# M411_unitA register map
File version: 2.0.2.2
Registers are 32-bit, read-write, reset 0x0 unless marked. A register's access mark holds for its fields unless they carry their own. Offsets are from the block's base; [hi:lo] are bit positions; {n}, {i} and the like mark numbered series.

## T16A0 — 16-bit TimerA (T16A)
Base 0x4008D000
Same registers: T16A1 0x4008E000
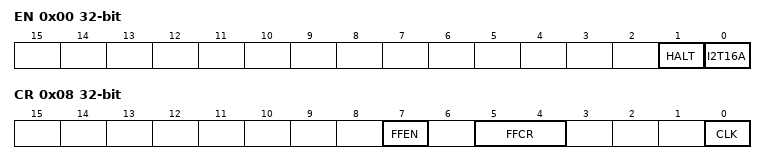
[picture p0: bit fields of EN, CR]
0x00 EN — Enable Register
  [1] HALT, [0] I2T16A
0x04 RUN
  [0] RUN
0x08 CR — Control Register
  [7] FFEN, [5:4] FFCR wo, [0] CLK
0x0C RG — Timer Register
  [15:0] RG
0x10 CP ro — Capture Register
  [15:0] CP

## I2C — I2C Bus Interface (I2C)
Base 0x400A0000
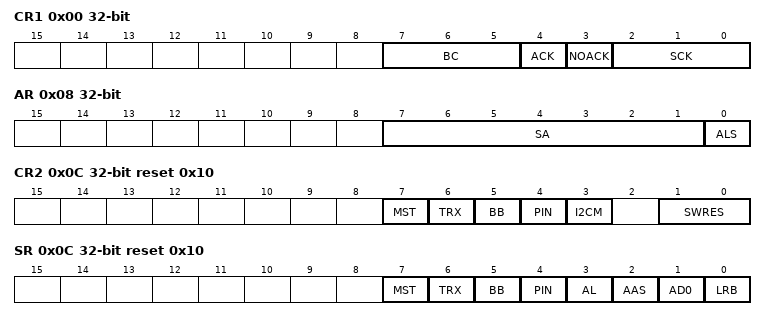
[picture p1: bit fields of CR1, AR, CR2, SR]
0x00 CR1 — I2C Control Register 1
  [7:5] BC, [4] ACK, [3] NOACK ro, [2:0] SCK
0x04 DBR — Data Buffer Register
  [7:0] DB
0x08 AR — Bus address Register
  [7:1] SA, [0] ALS
0x0C CR2 wo reset 0x10 — Control Register 1
  [7] MST, [6] TRX, [5] BB, [4] PIN, [3] I2CM, [1:0] SWRES
0x0C SR ro reset 0x10 — Status Register
  [7] MST, [6] TRX, [5] BB, [4] PIN, [3] AL, [2] AAS, [1] AD0, [0] LRB
0x10 PRS reset 0x1 — Prescaler clcok setting Register
  [4:0] PRSCK
0x14 IE — Interrupt Enable Register
  [0] IE
0x18 IR — Interrupt Register
  [0] ISIC

## INT — Interrupt Controller (INT)
Base 0x400B8000
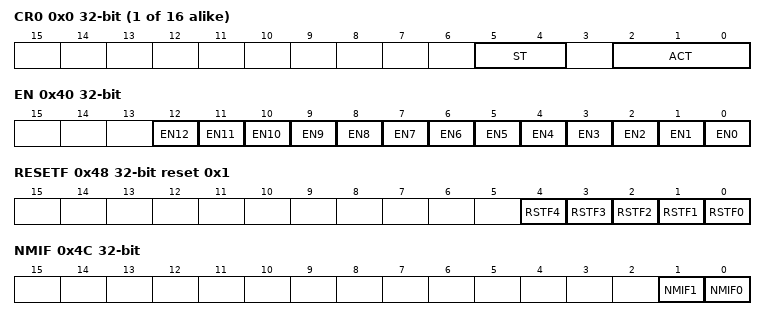
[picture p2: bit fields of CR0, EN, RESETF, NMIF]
{0x0+4i} CR{i} (i=0..15) — Control Register {i}
  [5:4] ST ro, [2:0] ACT
0x40 EN — STOP1 Mode Release Setting Register
  [n] EN{n} (n=0..12)
0x44 CLR wo — Interrupt Request Clear Register
  [3:0] CLR
0x48 RESETF reset 0x1 — Reset Flag Register
  [n] RSTF{n} (n=0..4)
0x4C NMIF ro — NMI Flag Register
  [1] NMIF1, [0] NMIF0
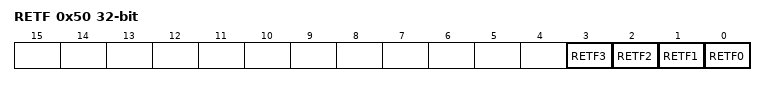
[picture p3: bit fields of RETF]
0x50 RETF — STOP2_STOP3 Release Flag Register
  [n] RETF{n} (n=0..3)
0x54 LVDST ro — SD2 Area Voltage Status Register
  [0] LVDST

## CPUIF — CPU Interface (CPUIF)
Base 0x400BC000
0x00 INTCR — Interrupt Control Regiser
  [0] INT
0x04 INTCLR — Interrupt Clear Register
  [0] CLR
0x08 INFOW — Transmit Data Register
0x0C INFOR ro reset not defined — Receive Data Register
0x10 CKCR — Clock Control Register for Unit B
  [0] CK
0x14 RSTCR — Reset Control Register for Unit B
  [0] RSTREL

## PA — Port A (PA)
Base 0x400C0000
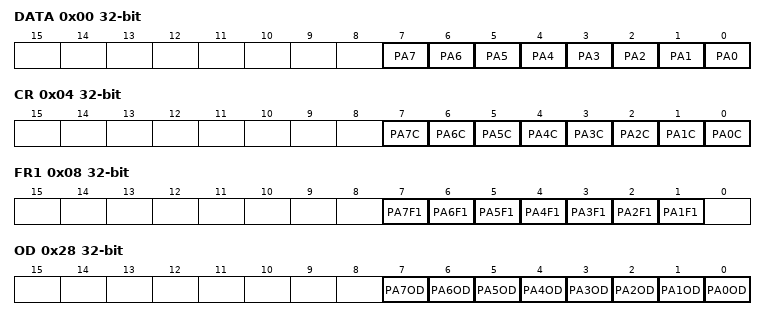
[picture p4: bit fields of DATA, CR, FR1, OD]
0x00 DATA — Port A Data Register
  [n] PA{n} (n=0..7)
0x04 CR — Port A Output Control Register
  [n] PA{n}C (n=0..7)
0x08 FR1 — Port A Function Register 1
  [n] PA{n}F1 (n=1..7)
0x28 OD — Port A Open-drain Control Register
  [n] PA{n}OD (n=0..7)
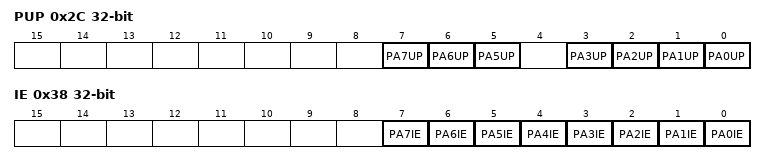
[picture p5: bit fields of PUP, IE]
0x2C PUP — Port A Pull-up Control Register
  [7] PA7UP, [6] PA6UP, [5] PA5UP, [n] PA{n}UP (n=0..3)
0x30 PDN — Port A Pull-down Control Register
  [4] PA4DN
0x38 IE — Port A Input Control Register
  [n] PA{n}IE (n=0..7)

## PB — Port B (PB)
Base 0x400C0100
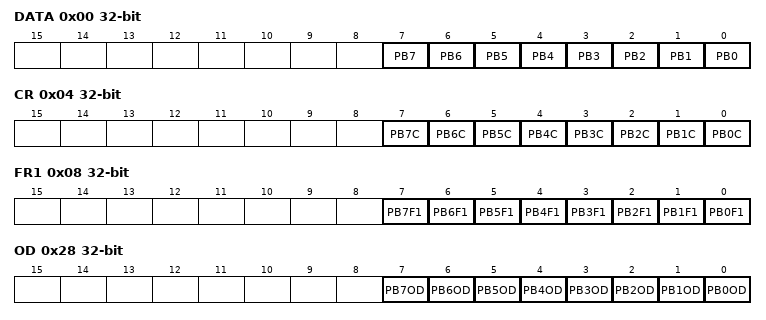
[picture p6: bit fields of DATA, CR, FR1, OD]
0x00 DATA — Port B Data Register
  [n] PB{n} (n=0..7)
0x04 CR — Port B Output Control Register
  [n] PB{n}C (n=0..7)
0x08 FR1 — Port B Function Register 1
  [n] PB{n}F1 (n=0..7)
0x28 OD — Port B Open-drain Control Register
  [n] PB{n}OD (n=0..7)
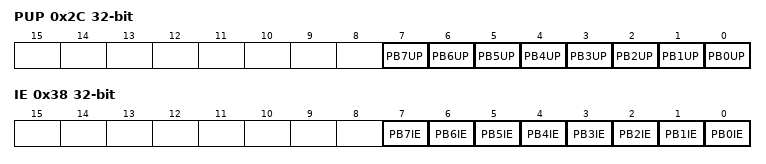
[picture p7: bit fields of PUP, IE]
0x2C PUP — Port B Pull-up Control Register
  [n] PB{n}UP (n=0..7)
0x38 IE — Port B Input Control Register
  [n] PB{n}IE (n=0..7)

## PC — Port C (PC)
Base 0x400C0200
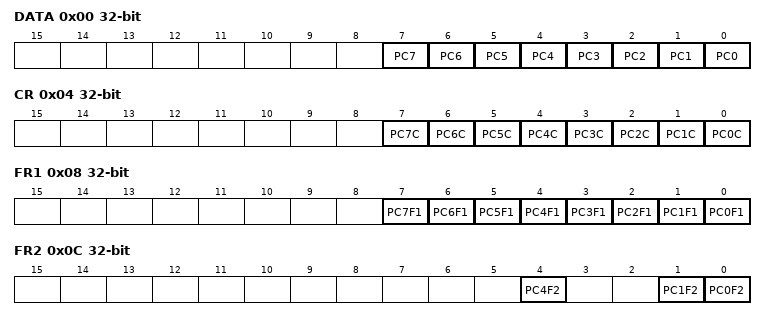
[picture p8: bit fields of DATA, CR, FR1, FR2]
0x00 DATA — Port C Data Register
  [n] PC{n} (n=0..7)
0x04 CR — Port C Output Control Register
  [n] PC{n}C (n=0..7)
0x08 FR1 — Port C Function Register 1
  [n] PC{n}F1 (n=0..7)
0x0C FR2 — Port C Function Register 2
  [4] PC4F2, [1] PC1F2, [0] PC0F2
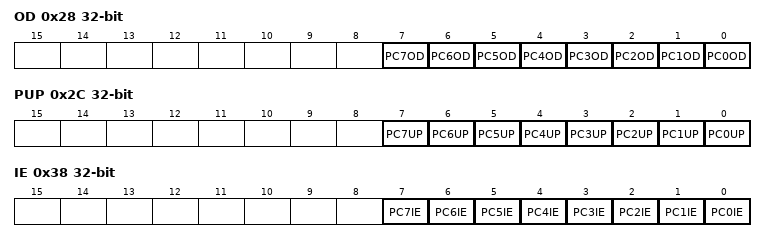
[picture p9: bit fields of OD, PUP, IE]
0x28 OD — Port C Open-drain Control Register
  [n] PC{n}OD (n=0..7)
0x2C PUP — Port C Pull-up Control Register
  [n] PC{n}UP (n=0..7)
0x38 IE — Port C Input Control Register
  [n] PC{n}IE (n=0..7)

## PD — Port D (PD)
Base 0x400C0300
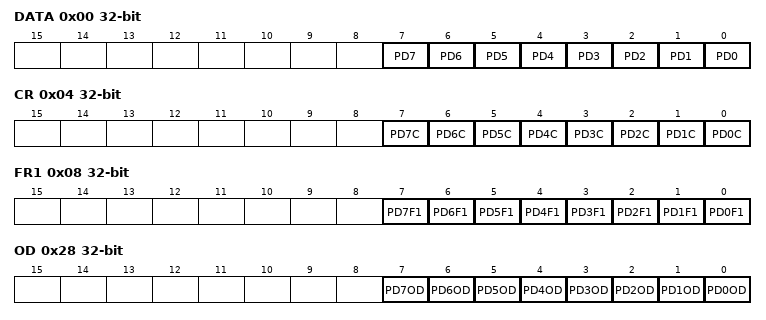
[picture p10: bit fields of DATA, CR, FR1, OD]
0x00 DATA — Port D Data Register
  [n] PD{n} (n=0..7)
0x04 CR — Port D Output Control Register
  [n] PD{n}C (n=0..7)
0x08 FR1 — Port D Function Register 1
  [n] PD{n}F1 (n=0..7)
0x28 OD — Port D Open-drain Control Register
  [n] PD{n}OD (n=0..7)
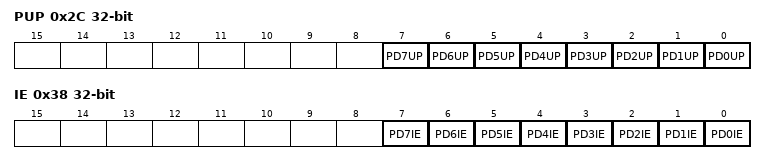
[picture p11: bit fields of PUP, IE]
0x2C PUP — Port D Pull-up Control Register
  [n] PD{n}UP (n=0..7)
0x38 IE — Port D Input Control Register
  [n] PD{n}IE (n=0..7)

## PE — Port E (PE)
Base 0x400C0400
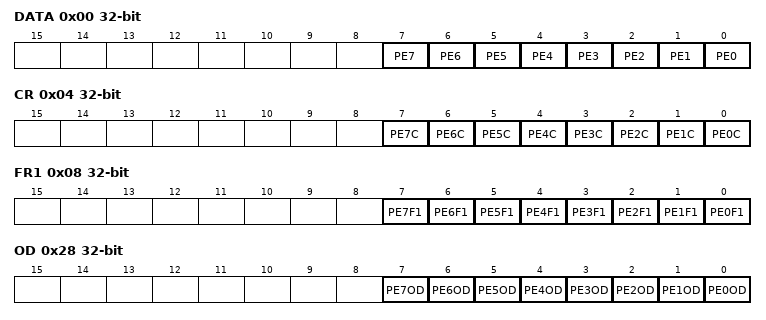
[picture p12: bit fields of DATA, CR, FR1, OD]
0x00 DATA — Port E Data Register
  [n] PE{n} (n=0..7)
0x04 CR — Port E Output Control Register
  [n] PE{n}C (n=0..7)
0x08 FR1 — Port E Function Register 1
  [n] PE{n}F1 (n=0..7)
0x0C FR2 — Port E Function Register 2
  [6] PE6F2
0x28 OD — Port E Open-drain Control Register
  [n] PE{n}OD (n=0..7)
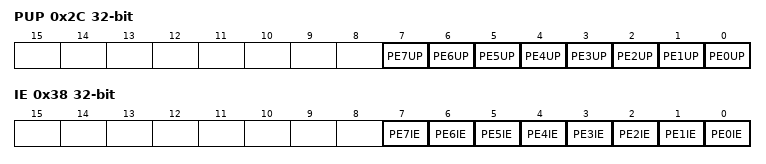
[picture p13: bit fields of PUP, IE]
0x2C PUP — Port E Pull-up Control Register
  [n] PE{n}UP (n=0..7)
0x38 IE — Port E Input Control Register
  [n] PE{n}IE (n=0..7)
